# hssi_ss_csr: IP-XACT component
VLNV Vendor:Library:hssi_ss_csr:1.0

## Bus interfaces (logical=physical port)
hssi_ss_csr_slave: slave Magillem:MRV:MRVBusDef:1.0, memory map hssi_ss_csr
  parameters _mre_definition_=hssi_ss_csr

## Address spaces and blocks
hssi_ss_csr.hssi_ss_csr_block: base 0x0, range 0x118, width 32, register

## Registers
Registers are 32-bit, read-only, reset 0x0 unless marked. A register's access mark holds for its fields unless they carry their own. Offsets are from the block's base; lines under a group give offsets from that group; [hi:lo] are bit positions; {n}, {i} and the like mark numbered series; 'fields as' and 'values as' point back to an identical list; <NAME> marks a mode.

## hssi_ss_csr.hssi_ss_csr_block
Base 0x00000000
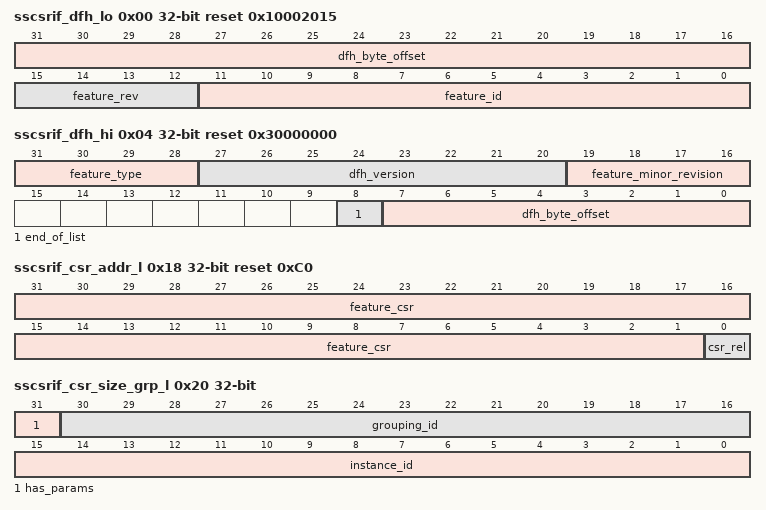
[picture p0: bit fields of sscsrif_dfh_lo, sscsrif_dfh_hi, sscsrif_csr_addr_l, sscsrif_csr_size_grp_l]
0x00 sscsrif_dfh_lo reset 0x10002015 — <b>Device Feature Header Lo </b>
  [31:16] dfh_byte_offset — <b>Next DFH Byte Offset Bit [15:0]</b> <b>Next DFH Address = 0x1000 (Current DFH Address + Next DFH Byte Offset Used to figure out Next DFH Address and as an indication for the maximum size of MMIO region occupied by this feature.</b> <b>For last feature, this offset points to the beginning of the unallocated MMIO region, if any (or beyond the end of the MMIOspace). </b>
  [15:12] feature_rev — <b>Feature Revision </b>
  [11:0] feature_id — <b>Feature ID </b>
0x04 sscsrif_dfh_hi reset 0x30000000 — <b>Device Feature Header Hi </b>
  [31:28] feature_type — <b>Feature Type </b> <p>4'b0011 - v0 feature/interface </p>
  [27:20] dfh_version — <b> DFH Version. It is 0 is CSR doesn't exist and 1 if CSR exist(for OSC).As per HAS, current version is v0.5 , till it is approved dfh version has to be 0x0 </b>
  [19:16] feature_minor_revision — <b> Feature Minor Revision </b>
  [8] end_of_list — <b>End of List </b> <p>1'b0 = This is last feature header (see Next DFH Byte Offset) </p>
  [7:0] dfh_byte_offset — <b>Next DFH Byte Offset Bit [39:32]</b> <b>Next DFH Address = 0x00 (Current DFH Address + Next DFH Byte Offset Used to figure out Next DFH Address and as an indication for the maximum size of MMIO region occupied by this feature.</b> <b>For last feature, this offset points to the beginning of the unallocated MMIO region, if any (or beyond the end of the MMIO space). </b>
0x08 sscsrif_feature_guid_l_low reset 0x18418B9D — <b> Feature GUID_L </b>
  [31:0] low_guid — <b> lower 32 bit of Low 64-bit of GUID </b>
0x0C sscsrif_feature_guid_l_high reset 0x99A078AD — <b> Feature GUID_L </b>
  [31:0] low_guid — <b> upper 32bit of Low 64-bit of GUID </b>
0x10 sscsrif_feature_guid_h_low reset 0xD9DB4A9B — <b> Feature GUID_H </b>
  [31:0] high_guid — <b> lower 32 bit of High 64-bit of GUID </b>
0x14 sscsrif_feature_guid_h_high reset 0x4118A7CB — <b> Feature GUID_H </b>
  [31:0] high_guid — <b> higher 32 bit of High 64-bit of GUID </b>
0x18 sscsrif_csr_addr_l reset 0xC0 — <b> Feature CSR ADDR </b>
  [31:1] feature_csr — <b> Points to where the IP/SS proprietary feature CSRs start. </b> <b> Need to provision space for future std DFH registers to grow </b> <b> For all IP/SS, this field shall point to 0x60 </b>
  [0] csr_rel — <b> Point to CSR located in a different address space which may be outside of PCI BAR, mainly for ARM </b> <b> 1'b0 = relative (offset from feature DFH start),1'b1 = absolute </b> <b> For all IP/SS, this field shall be 1b0. </b>
0x1C sscsrif_csr_addr_h — <b> Feature CSR ADDR </b>
  [31:0] feature_csr — <b> Points to where the IP/SS proprietary feature CSRs start. </b> <b> Need to provision space for future std DFH registers to grow </b> <b> For all IP/SS, this field shall point to 0x60 </b>
0x20 sscsrif_csr_size_grp_l — <b> Feature CSR Size Group </b>
  [31] has_params — <b> Indicates whether the optional Param Header and Param Y CSR are present or not. </b> <b> For all IP/SS, this field shall be 1b0 (no Param Header and no Param Y CSR) </b>
  [30:16] grouping_id — <b> Used to group features / interfaces . To differentiate & group different blocks within the pipeline </b> <b> For all IP/SS, this field is driver to zeros. </b>
  [15:0] instance_id — <b> Enumeration of instantiated IP </b> <b> A counter to differentiate each instances of the IP, advertise the instance ID assigned by Quartus </b> <b> To allow software to build the graph. Value derived from DFHv1_INSTID parameter </b>
0x24 sscsrif_csr_size_grp_h reset 0x44 — <b> Feature CSR Size Group </b>
  [31:0] csr_size — <b> Size of CSR block in bytes </b> <b> Specifies the size of the IP/SS proprietary feature CSR in Bytes </b>
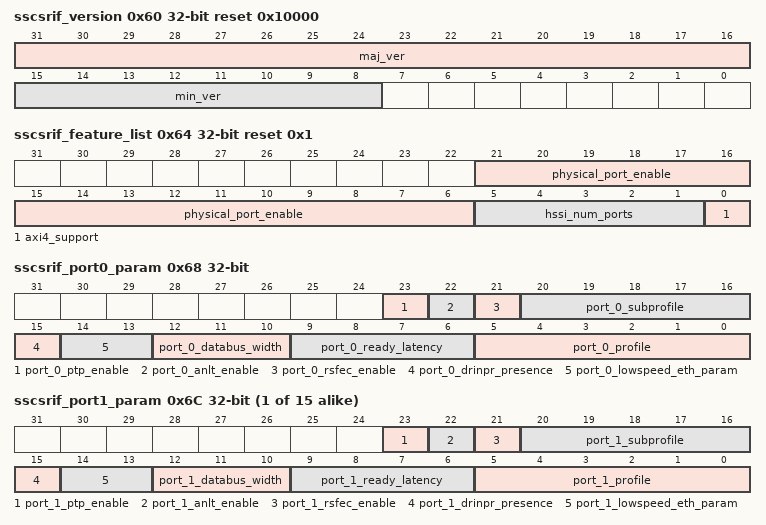
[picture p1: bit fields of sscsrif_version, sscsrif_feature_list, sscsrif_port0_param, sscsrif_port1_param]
0x60 sscsrif_version reset 0x10000 — <b>Version </b>
  [31:16] maj_ver — <b>Major Version Number (MNR): Indicates the Major version.</b>
  [15:8] min_ver — <b>Minor Version Number (MNR): Indicates the minor version.</b>
0x64 sscsrif_feature_list reset 0x1 — <b>Feature List </b>
  [21:6] physical_port_enable — <b>Physical Port Enable </b> <p>[ 6] - Port 0 Enable </p> <p>[ 7] - Port 1 Enable </p> <p> . </p> <p> . </p> <p>[21] - Port 15 Enable </p>
  [5:1] hssi_num_ports — <b>Number of HSSI Ports Instantiated (NUM_PORTS parameter) </b>
  [0] axi4_support — <b>AXI-4 Support </b>
0x68 sscsrif_port0_param — <b>Interface Attribute Port 0 Parameters, (Depends on NUM_PORTS parameter, read returns reserved value 0 if port does not exist) </b>
  [23] port_0_ptp_enable — <b>PTP Enabled </b>
  [22] port_0_anlt_enable — <b>ANLT Enabled </b>
  [21] port_0_rsfec_enable — <b>RSFEC Enabled </b>
  [20:16] port_0_subprofile — <b>Port 0 Sub-Profiles. </b> <p>5'b10000 and above - Reserved</p> <p>5'b01111 - 24G PCS </p> <p>5'b01110 - 12G PCS </p> <p>5'b01101 - 10G PCS </p> <p>5'b01100 - 9.8G PMA </p> <p>5'b01011 - 8.1G PMA </p> <p>5'b01010 - 6.1G PMA </p> <p>5'b01001 - 4.9G PMA </p> <p>5'b01000 - 3.0G PMA </p> <p>5'b00111 - 2.4G PMA </p> <p>5'b00110 - 1.2G PMA </p> <p>5'b00101 - 0.6G PMA </p> <p>5'b00100 - MAC + PCS </p> <p>5'b00011 - PCS </p> <p>5'b00010 - FlexE </p> <p>5'b00001 - OTN </p> <p>5'b00000 - None </p>
  [15] port_0_drinpr_presence — <b>Indicate presence of Dynamic Reconfiguration in Partial Reconfiguration use case.</b> <p>1: Dynamic Reconfiguration in Partial Reconfiguration use case presence </p> <p>0: Dynamic Reconfiguration in Partial Reconfiguration use case not presence </p>
  [14:13] port_0_lowspeed_eth_param — <b>Low Speed Ethernet MAC Interface (PORT0_LOW_SPEED_ETH parameter).</b> <p>2'b10: XGMII </p> <p>2'b01: GMII </p> <p>2'b00: MII </p>
  [12:10] port_0_databus_width — <b>Port 0 Data Bus Width (PORT0_DATA_WIDTH parameter).</b> <p>3'b101: 1024 </p> <p>3'b100: 512 </p> <p>3'b011: 256 </p> <p>3'b010: 128 </p> <p>3'b001: 64 </p> <p>3'b000: 32 </p>
  [9:6] port_0_ready_latency — <b>Port 0 Ready Latency (PORT0_READY_LATENCY parameter).</b>
  [5:0] port_0_profile — <b>Port 0 Profiles (PORT0_PROFILE).</b> <p>6'b100000: 400GAUI-8, </p> <p>6'b011111: 400GAUI-4, </p> <p>6'b011110: 200GAUI-8, </p> <p>6'b011101: 200GAUI-4, </p> <p>6'b011100: 200GAUI-2, </p> <p>6'b011011: 100GCAUI-4, </p> <p>6'b011010: 100GAUI-2, </p> <p>6'b011001: 100GAUI-1, </p> <p>6'b011000: 50GAUI-1, </p> <p>6'b010111: 50GAUI-2, </p> <p>6'b010110: 40GCAUI-4, </p> <p>6'b010101: 25GbE, </p> <p>6'b010100: 10GbE, </p> <p>6'b010011: Ethernet PMA-Direct,</p> <p>6'b010010: Ethernet FEC-Direct,</p> <p>6'b010001: Ethernet PCS-Direct,</p> <p>6'b010000: MII, </p> <p>6'b001111: General PMA-Direct, </p> <p>6'b001110: General FEC-Direct, </p> <p>6'b001101: General PCS-Direct, </p> <p>6'b001100: OTN, </p> <p>6'b001011: Flex-E, </p> <p>6'b001010: TSE MAC, </p> <p>6'b001001: TSE PCS, </p> <p>6'b001000: LL10G, </p> <p>6'b000111: MRPHY, </p> <p>6'b000110: 10_25G, </p> <p>6'b000101: 25_50G, </p> <p>6'b000100: Ultra40G, </p> <p>6'b000011: LL40G, </p> <p>6'b000010: LL50G, </p> <p>6'b000001: Ultra100G, </p> <p>6'b000000: LL100G </p>
{0x68+4i} sscsrif_port{i}_param (i=1..15) — <b>Interface Attribute Port {i} Parameters, (Depends on NUM_PORTS parameter, read returns reserved value 0 if port does not exist) </b>
  [23] port_{i}_ptp_enable — <b>PTP Enabled </b>
  [22] port_{i}_anlt_enable — <b>ANLT Enabled </b>
  [21] port_{i}_rsfec_enable — <b>RSFEC Enabled </b>
  [20:16] port_{i}_subprofile — <b>Port {i} Sub-Profiles.</b> <p>6'b100000: 400GAUI-8, </p> <p>6'b011111: 400GAUI-4, </p> <p>6'b011110: 200GAUI-8, </p> <p>6'b011101: 200GAUI-4, </p> <p>6'b011100: 200GAUI-2, </p> <p>6'b011011: 100GCAUI-4, </p> <p>6'b011010: 100GAUI-2, </p> <p>6'b011001: 100GAUI-1, </p> <p>6'b011000: 50GAUI-1, </p> <p>6'b010111: 50GAUI-2, </p> <p>6'b010110: 40GCAUI-4, </p> <p>6'b010101: 25GbE, </p> <p>6'b010100: 10GbE, </p> <p>6'b010011: Ethernet PMA-Direct,</p> <p>6'b010010: Ethernet FEC-Direct,</p> <p>6'b010001: Ethernet PCS-Direct,</p> <p>6'b010000: MII, </p> <p>6'b001111: General PMA-Direct, </p> <p>6'b001110: General FEC-Direct, </p> <p>6'b001101: General PCS-Direct, </p> <p>6'b001100: OTN, </p> <p>6'b001011: Flex-E, </p> <p>6'b001010: TSE MAC, </p> <p>6'b001001: TSE PCS, </p> <p>6'b001000: LL10G, </p> <p>6'b000111: MRPHY, </p> <p>6'b000110: 10_25G, </p> <p>6'b000101: 25_50G, </p> <p>6'b000100: Ultra40G, </p> <p>6'b000011: LL40G, </p> <p>6'b000010: LL50G, </p> <p>6'b000001: Ultra100G, </p> <p>6'b000000: LL100G </p>
  [15] port_{i}_drinpr_presence — <b>Indicate presence of Dynamic Reconfiguration in Partial Reconfiguration use case.</b> <p>1: Dynamic Reconfiguration in Partial Reconfiguration use case presence </p> <p>0: Dynamic Reconfiguration in Partial Reconfiguration use case not presence </p>
  [14:13] port_{i}_lowspeed_eth_param — <b>Low Speed Ethernet MAC Interface (PORT{i}_LOW_SPEED_ETH parameter).</b> <p>2'b10: XGMII </p> <p>2'b01: GMII </p> <p>2'b00: MII </p>
  [12:10] port_{i}_databus_width — <b>Port {i} Data Bus Width (PORT{i}_DATA_WIDTH parameter).</b> <p>3'b101: 1024 </p> <p>3'b100: 512 </p> <p>3'b011: 256 </p> <p>3'b010: 128 </p> <p>3'b001: 64 </p> <p>3'b000: 32 </p>
  [9:6] port_{i}_ready_latency — <b>Port {i} Ready Latency (PORT{i}_READY_LATENCY parameter).</b>
  [5:0] port_{i}_profile — <b>Port {i} Profiles (PORT{i}_PROFILE).</b> <p>6'b100000: 400GAUI-8, </p> <p>6'b011111: 400GAUI-4, </p> <p>6'b011110: 200GAUI-8, </p> <p>6'b011101: 200GAUI-4, </p> <p>6'b011100: 200GAUI-2, </p> <p>6'b011011: 100GCAUI-4, </p> <p>6'b011010: 100GAUI-2, </p> <p>6'b011001: 100GAUI-1, </p> <p>6'b011000: 50GAUI-1, </p> <p>6'b010111: 50GAUI-2, </p> <p>6'b010110: 40GCAUI-4, </p> <p>6'b010101: 25GbE, </p> <p>6'b010100: 10GbE, </p> <p>6'b010011: Ethernet PMA-Direct,</p> <p>6'b010010: Ethernet FEC-Direct,</p> <p>6'b010001: Ethernet PCS-Direct,</p> <p>6'b010000: MII, </p> <p>6'b001111: General PMA-Direct, </p> <p>6'b001110: General FEC-Direct, </p> <p>6'b001101: General PCS-Direct, </p> <p>6'b001100: OTN, </p> <p>6'b001011: Flex-E, </p> <p>6'b001010: TSE MAC, </p> <p>6'b001001: TSE PCS, </p> <p>6'b001000: LL10G, </p> <p>6'b000111: MRPHY, </p> <p>6'b000110: 10_25G, </p> <p>6'b000101: 25_50G, </p> <p>6'b000100: Ultra40G, </p> <p>6'b000011: LL40G, </p> <p>6'b000010: LL50G, </p> <p>6'b000001: Ultra100G, </p> <p>6'b000000: LL100G </p>
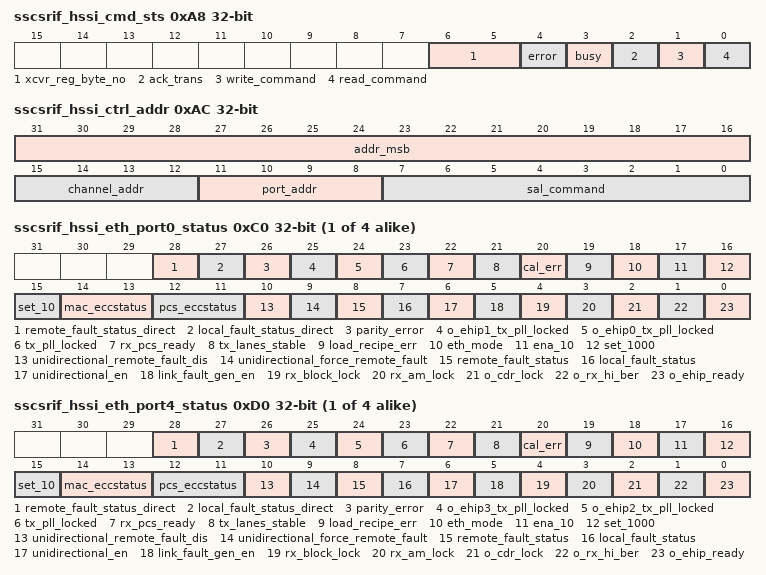
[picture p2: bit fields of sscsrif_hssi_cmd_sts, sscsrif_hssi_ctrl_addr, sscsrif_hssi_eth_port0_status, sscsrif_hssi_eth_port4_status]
0xA8 sscsrif_hssi_cmd_sts rw — <b>HSSI Command/Status </b>
  [6:5] xcvr_reg_byte_no — <b>XCVR Reg Byte Num </b>
  [4] error ro
  [3] busy ro
  [2] ack_trans — <b>ACK_TRANS: Bit gets asserted by hw when transaction is complete. Gets cleared by hw, when hw receives the next command. </b> <p> 0- indicates, a command is getting processed.</p> <p> 1- Indicates, the earlier command processing is complete and it's ready to accept next command.</p>
  [1] write_command — <b>Write Command </b>
  [0] read_command — <b>Read Command </b>
0xAC sscsrif_hssi_ctrl_addr rw — <b>HSSI Control 1 </b>
  [31:16] addr_msb — <b>Address bit [23:8] </b>
  [15:12] channel_addr — <b>Channel/Address:</b> <p>When SAL command = get_hssi_profile, set_hssi_profile, enable loopback, disable loopback, [15:12] = Channel</p> <p>When SAL command = get_csr, set_csr, [15:12] = Address[7:4]</p> <p>Others, [15:12] = 4'b0 </p>
  [11:8] port_addr — <b>Port/Address: </b> <p>When SAL command = get_hssi_profile, set_hssi_profile, enable loopback, disable loopback, [11:8] = Port</p> <p>When SAL command = get_csr, set_csr, [11:8] = Address[3:0]</p> <p>Others[11:8] = 4'b0 </p>
  [7:0] sal_command — <b>RSAL Command:</b> <p>0x0 NOP </p> <p>0x1 get_hssi_profile </p> <p>0x2 set_hssi_profile </p> <p>0x3 read_MAC_statistic </p> <p>0x4 get_mtu </p> <p>0x5 Set CSR </p> <p>0x6 Get CSR </p> <p>0x7 Enable loopback </p> <p>0x8 Disable loopback </p> <p>0x9 - 0xFE reserved </p> <p>0xFF firmware_versionserved </p>
0xB0 sscsrif_hssi_rd_data — <b>HSSI Read Data </b>
  [31:0] write_data — <b>Read data </b>
0xB4 sscsrif_hssi_wr_data rw — <b>HSSI Write Data </b>
  [31:0] write_data — <b>Write data </b>
0xB8 sscsrif_gmii_xgmii_tx_latency — <b>GMII/XGMII TX Latency </b>
  [23:0] tx_latency — <b>gmii_tx_latency/xgmii_tx_latency </b> <b>The latency of the PHY excluding the PMA block on the TX datapath:</b> <p>Bits [15:10], [21:10] and [23:10]: The number of clock cycles.</p> <p>Bits [9:0]: The fractional number of clock cycles.</p> <p>The width is:</p> <p>16 bits for 1G/2.5G/10G (MGBASE-T) with IEEE 1588 configurations.</p> <p>22 bits for 2.5G, 1G/2.5G, 10M/100M/1G/2.5G, 1G/2.5G/10G (MGBASE-T),10M/100M/1G/2.5G/10G(MGBASE-T)</p> <p>24 bits for 10M/100M/1G/2.5G/5G/10G (USXGMII) configurations.</p> <b>This signal is available when only the Enable IEEE 1588 Precision Time Protocol parameter is selected.</b> <b>Note:</b> <b>For USXGMII configuration, the latency value may be unstable for the first three transmitted packets times (at least 64 bytes). You should not use the latency value within this period. Only applicable for MRPHY profile. Reserved for other profiles.</b>
0xBC sscsrif_gmii_xgmii_rx_latency — <b>GMII/XGMII RX Latency </b>
  [23:0] rx_latency — <b>gmii_rx_latency/xgmii_rx_latency </b> <b>The latency of the PHY excluding the PMA block on the TX datapath:</b> <p>Bits [15:10], [21:10] and [23:10]: The number of clock cycles.</p> <p>Bits [9:0]: The fractional number of clock cycles.</p> <p>The width is:</p> <p>16 bits for 1G/2.5G/10G (MGBASE-T) with IEEE 1588 configurations.</p> <p>22 bits for 2.5G, 1G/2.5G, 10M/100M/1G/2.5G, 1G/2.5G/10G (MGBASE-T),10M/100M/1G/2.5G/10G(MGBASE-T)</p> <p>24 bits for 10M/100M/1G/2.5G/5G/10G (USXGMII) configurations.</p> <b>This signal is available when only the Enable IEEE 1588 Precision Time Protocol parameter is selected.</b> <b>Note:</b> <b>For USXGMII configuration, the latency value may be unstable for the first three transmitted packets times (at least 64 bytes). You should not use the latency value within this period. Only applicable for MRPHY profile. Reserved for other profiles.</b>
{0xC0+4i} sscsrif_hssi_eth_port{i}_status rw (i=0..3) — <b>HSSI Ethernet port{i} Status (Depends on NUM_PORTS parameter, read returns reserved value 0 if port does not exist) </b>
  [28] remote_fault_status_direct ro — <b>remote_fault_status:</b> <p>Asserted when the RX MAC of the corresponding Ethernet channel detects a remote fault: the remote link partner sent remote fault ordered sets indicating that it is unable to receive data. This signal is functional only if you set the Choose Link Fault generation option parameter to the value of Bidirectional in the parameter editor or if you overwrite the parameter editor parameter by setting the link_fault_mode RTL parameter to the value of lf_bidir.</p>
  [27] local_fault_status_direct ro — <b>local_fault_status:</b> <p>Asserted when the RX MAC of the corresponding Ethernet channel detects a local fault: the RX PCS detected a problem that prevents it from receiving data. This signal is functional only if you set the Choose Link Fault generation option parameter to the value of Bidirectional or Unidirectional in the parameter editor or if you overwrite the parameter editor parameter by setting the link_fault_mode RTL parameter to the value of lf_bidir or lf_unidir. </p>
  [26] parity_error write-1-clears — <b>Parity Error on received packet </b>
  [25] o_ehip1_tx_pll_locked ro — <b>o_ehip1_tx_pll_locked: </b> <p> PTP channels Tx_pll_locked (o_ehip{0..NUM_PORT/2}_tx_pll_locked, applicable only in E-tile. </p>
  [24] o_ehip0_tx_pll_locked ro — <b>o_ehip0_tx_pll_locked: </b> <p> PTP channels Tx_pll_locked (o_ehip{0..NUM_PORT/2}_tx_pll_locked, applicable only in E-tile. </p>
  [23] tx_pll_locked ro — <b>Tx_pll_locked: </b> <p> Tx Ethernet port pll lock </p>
  [22] rx_pcs_ready ro — <b>Rx_pcs_ready:</b> <p> Asserted when the RX lanes of the corresponding Ethernet port are fully aligned and ready to receive data. </p>
  [21] tx_lanes_stable ro — <b>Tx_lanes_stable:</b> <p> Asserted when physical TX lanes are stable and ready to transmit data for the corresponding Ethernet port. </p>
  [20] cal_err ro — <b>cal_err:</b> <p>Calibration Error Status.This bit reports the error status of ical/pcal at power on. </p>
  [19] load_recipe_err ro — <b>load_recipe_err:</b> <p>Load Recipe Error Status.This bit reports the error status of load PMA recipe at power on. </p>
  [18] eth_mode ro — <b>eth_mode:</b> <p>Ethernet mode. This signal is set to 1 when the MAC function is configured to operate at 1000 Mbps; set to 0 when it is configured to operate at 10/100 Mbps. Only applicable for TSE_MAC profile. Reserved for other profiles. </p>
  [17] ena_10 ro — <b>ena_10:</b> <p>10 Mbps enable. This signal is set to 1 to indicate that the PHY interface should operate at 10 Mbps. Valid only when the eth_mode signal is set to 0. Only applicable for TSE_MAC profile. Reserved for other profiles. </p>
  [16] set_1000 ro — <b>set_1000:</b> <p>Gigabit mode selection. Can be driven to 1 by an external device, for example a PHY device, to set the MAC function to operate in gigabit. When set to 0, the MAC is set to operate in 10/100 Mbps. This signal is ignored when the ETH_SPEED bit in the command_config register is set to 1. Only applicable for TSE_MAC profile. Reserved for other profiles. </p>
  [15] set_10 ro — <b>set_10:</b> <p>10 Mbps selection. Can be driven to 1 by an external device, for example a PHY device, to indicate that the MAC function is connected to a 10-Mbps PHY device. When set to 0, the MAC function is set to operate in 100-Mbps or gigabit mode. This signal is ignored when the ETH_SPEED or ENA_10 bit in the command_config register is set to 1. The ENA_10 bit has a higher priority than this signal. Only applicable for TSE_MAC profile. Reserved for other profiles. </p>
  [14:13] mac_eccstatus ro — <b>mac_eccstatus[1:0]:</b> <p>Indicates the ECC status. This signal is synchronized to the reg_clk clock domain. 11: An uncorrectable error occurred and the error data appears at the output. 10: A correctable error occurred and the error has been corrected at the output. However, the memory array has not been updated. 01: Not valid. 00: No error. Only applicable for TSE_MAC profile. Reserved for other profiles. </p>
  [12:11] pcs_eccstatus ro — <b>pcs_eccstatus[1:0]:</b> <p>Indicates the ECC status. This signal is synchronized to the reg_clk clock domain. 11: An uncorrectable error occurred and the error data appears at the output. 10: A correctable error occurred and the error has been corrected at the output. However, the memory array has not been updated. 01: Not valid. 00: No error Only applicable for TSE_PCS profile. Reserved for other profiles. </p>
  [10] unidirectional_remote_fault_dis ro — <b>unidirectional_remote_fault_dis:</b> <p>When asserted, this signal indicates the state of the tx_unidir_control register bit 1. </p>
  [9] unidirectional_force_remote_fault ro — <b>unidirectional_force_remote_fault:</b> <p>When asserted, this signal indicates the state of the tx_unidir_control register bit 2. </p>
  [8] remote_fault_status write-1-clears — <b>remote_fault_status:</b> <p>Asserted when the RX MAC of the corresponding Ethernet channel detects a remote fault: the remote link partner sent remote fault ordered sets indicating that it is unable to receive data. This signal is functional only if you set the Choose Link Fault generation option parameter to the value of Bidirectional in the parameter editor or if you overwrite the parameter editor parameter by setting the link_fault_mode RTL parameter to the value of lf_bidir.</p>
  [7] local_fault_status write-1-clears — <b>local_fault_status:</b> <p>Asserted when the RX MAC of the corresponding Ethernet channel detects a local fault: the RX PCS detected a problem that prevents it from receiving data. This signal is functional only if you set the Choose Link Fault generation option parameter to the value of Bidirectional or Unidirectional in the parameter editor or if you overwrite the parameter editor parameter by setting the link_fault_mode RTL parameter to the value of lf_bidir or lf_unidir. </p>
  [6] unidirectional_en ro — <b>unidirectional_en:</b> <p>Asserted if the IP core includes Clause 66 for unidirectional support. This signal is available if you turn on Enable link fault generation in the parameter editor. </p>
  [5] link_fault_gen_en ro — <b>link_fault_gen_en:</b> <p>Asserted if the IP core includes Clause 66 for unidirectional support. This signal is available if you turn on Enable link fault generation in the parameter editor. </p>
  [4] rx_block_lock ro — <b>rx_block_lock:</b> <p>Asserted when the corresponding Ethernet channel completes 66-bit block boundary alignment on all PCS lanes. Each channel has its own block lock signal. </p>
  [3] rx_am_lock ro — <b>rx_am_lock:</b> <p>Asserted when the RX PCS completes detection of alignment markers and deskew of the virtual PCS lanes in the corresponding Ethernet 100G channel. </p>
  [2] o_cdr_lock ro — <b>o_cdr_lock:</b> <p>Indicates that the recovered clocks are locked to data. The o_clk_rec_div64[n] and o_clk_rec_div66[n] clocks are reliable only after o_cdr_lock[n] is asserted. </p>
  [1] o_rx_hi_ber ro — <b>o_rx_hi_ber:</b> <p>Asserted to indicate the RX PCS of the corresponding Ethernet channel is in a HI BER state according to Figure 82-15 in the IEEE 802.3- 2015 Standard. The IP core uses this signal in autonegotiation and link training. </p>
  [0] o_ehip_ready ro — <b>o_ehip_ready:</b> <p>The Ethernet channel deasserts this signal in response to an i_csr_rst_n or i_tx_rst_n reset, or either of the corresponding soft resets. After the reset process completes, the channel reasserts this signal to indicate that the Hard IP for Ethernet block has completed initialization and is ready to interoperate with the main Intel Stratix 10 die. While the o_ehip_ready signal is low, the channel's datapath is not ready for data on the client interface nor ready for register accesses on the Ethernet reconfiguration interface.</p>
{0xC0+4i} sscsrif_hssi_eth_port{i}_status rw (i=4..7) — <b>HSSI Ethernet port{i} Status (Depends on NUM_PORTS parameter, read returns reserved value 0 if port does not exist) </b>
  [28] remote_fault_status_direct ro — <b>remote_fault_status:</b> <p>Asserted when the RX MAC of the corresponding Ethernet channel detects a remote fault: the remote link partner sent remote fault ordered sets indicating that it is unable to receive data. This signal is functional only if you set the Choose Link Fault generation option parameter to the value of Bidirectional in the parameter editor or if you overwrite the parameter editor parameter by setting the link_fault_mode RTL parameter to the value of lf_bidir.</p>
  [27] local_fault_status_direct ro — <b>local_fault_status:</b> <p>Asserted when the RX MAC of the corresponding Ethernet channel detects a local fault: the RX PCS detected a problem that prevents it from receiving data. This signal is functional only if you set the Choose Link Fault generation option parameter to the value of Bidirectional or Unidirectional in the parameter editor or if you overwrite the parameter editor parameter by setting the link_fault_mode RTL parameter to the value of lf_bidir or lf_unidir. </p>
  [26] parity_error write-1-clears — <b>Parity Error on received packet </b>
  [25] o_ehip3_tx_pll_locked ro — <b>o_ehip3_tx_pll_locked: </b> <p> PTP channels Tx_pll_locked (o_ehip{0..NUM_PORT/2}_tx_pll_locked, applicable only in E-tile. </p>
  [24] o_ehip2_tx_pll_locked ro — <b>o_ehip2_tx_pll_locked: </b> <p> PTP channels Tx_pll_locked (o_ehip{0..NUM_PORT/2}_tx_pll_locked, applicable only in E-tile. </p>
  [23] tx_pll_locked ro — <b>Tx_pll_locked: </b> <p> Tx Ethernet port pll lock </p>
  [22] rx_pcs_ready ro — <b>Rx_pcs_ready:</b> <p> Asserted when the RX lanes of the corresponding Ethernet port are fully aligned and ready to receive data. </p>
  [21] tx_lanes_stable ro — <b>Tx_lanes_stable:</b> <p> Asserted when physical TX lanes are stable and ready to transmit data for the corresponding Ethernet port. </p>
  [20] cal_err ro — <b>cal_err:</b> <p>Calibration Error Status.This bit reports the error status of ical/pcal at power on. </p>
  [19] load_recipe_err ro — <b>load_recipe_err:</b> <p>Load Recipe Error Status.This bit reports the error status of load PMA recipe at power on. </p>
  [18] eth_mode ro — <b>eth_mode:</b> <p>Ethernet mode. This signal is set to 1 when the MAC function is configured to operate at 1000 Mbps; set to 0 when it is configured to operate at 10/100 Mbps. Only applicable for TSE_MAC profile. Reserved for other profiles. </p>
  [17] ena_10 ro — <b>ena_10:</b> <p>10 Mbps enable. This signal is set to 1 to indicate that the PHY interface should operate at 10 Mbps. Valid only when the eth_mode signal is set to 0. Only applicable for TSE_MAC profile. Reserved for other profiles. </p>
  [16] set_1000 ro — <b>set_1000:</b> <p>Gigabit mode selection. Can be driven to 1 by an external device, for example a PHY device, to set the MAC function to operate in gigabit. When set to 0, the MAC is set to operate in 10/100 Mbps. This signal is ignored when the ETH_SPEED bit in the command_config register is set to 1. Only applicable for TSE_MAC profile. Reserved for other profiles. </p>
  [15] set_10 ro — <b>set_10:</b> <p>10 Mbps selection. Can be driven to 1 by an external device, for example a PHY device, to indicate that the MAC function is connected to a 10-Mbps PHY device. When set to 0, the MAC function is set to operate in 100-Mbps or gigabit mode. This signal is ignored when the ETH_SPEED or ENA_10 bit in the command_config register is set to 1. The ENA_10 bit has a higher priority than this signal. Only applicable for TSE_MAC profile. Reserved for other profiles. </p>
  [14:13] mac_eccstatus ro — <b>mac_eccstatus[1:0]:</b> <p>Indicates the ECC status. This signal is synchronized to the reg_clk clock domain. 11: An uncorrectable error occurred and the error data appears at the output. 10: A correctable error occurred and the error has been corrected at the output. However, the memory array has not been updated. 01: Not valid. 00: No error. Only applicable for TSE_MAC profile. Reserved for other profiles. </p>
  [12:11] pcs_eccstatus ro — <b>pcs_eccstatus[1:0]:</b> <p>Indicates the ECC status. This signal is synchronized to the reg_clk clock domain. 11: An uncorrectable error occurred and the error data appears at the output. 10: A correctable error occurred and the error has been corrected at the output. However, the memory array has not been updated. 01: Not valid. 00: No error Only applicable for TSE_PCS profile. Reserved for other profiles. </p>
  [10] unidirectional_remote_fault_dis ro — <b>unidirectional_remote_fault_dis:</b> <p>When asserted, this signal indicates the state of the tx_unidir_control register bit 1. </p>
  [9] unidirectional_force_remote_fault ro — <b>unidirectional_force_remote_fault:</b> <p>When asserted, this signal indicates the state of the tx_unidir_control register bit 2. </p>
  [8] remote_fault_status write-1-clears — <b>remote_fault_status:</b> <p>Asserted when the RX MAC of the corresponding Ethernet channel detects a remote fault: the remote link partner sent remote fault ordered sets indicating that it is unable to receive data. This signal is functional only if you set the Choose Link Fault generation option parameter to the value of Bidirectional in the parameter editor or if you overwrite the parameter editor parameter by setting the link_fault_mode RTL parameter to the value of lf_bidir.</p>
  [7] local_fault_status write-1-clears — <b>local_fault_status:</b> <p>Asserted when the RX MAC of the corresponding Ethernet channel detects a local fault: the RX PCS detected a problem that prevents it from receiving data. This signal is functional only if you set the Choose Link Fault generation option parameter to the value of Bidirectional or Unidirectional in the parameter editor or if you overwrite the parameter editor parameter by setting the link_fault_mode RTL parameter to the value of lf_bidir or lf_unidir. </p>
  [6] unidirectional_en ro — <b>unidirectional_en:</b> <p>Asserted if the IP core includes Clause 66 for unidirectional support. This signal is available if you turn on Enable link fault generation in the parameter editor. </p>
  [5] link_fault_gen_en ro — <b>link_fault_gen_en:</b> <p>Asserted if the IP core includes Clause 66 for unidirectional support. This signal is available if you turn on Enable link fault generation in the parameter editor. </p>
  [4] rx_block_lock ro — <b>rx_block_lock:</b> <p>Asserted when the corresponding Ethernet channel completes 66-bit block boundary alignment on all PCS lanes. Each channel has its own block lock signal. </p>
  [3] rx_am_lock ro — <b>rx_am_lock:</b> <p>Asserted when the RX PCS completes detection of alignment markers and deskew of the virtual PCS lanes in the corresponding Ethernet 100G channel. </p>
  [2] o_cdr_lock ro — <b>o_cdr_lock:</b> <p>Indicates that the recovered clocks are locked to data. The o_clk_rec_div64[n] and o_clk_rec_div66[n] clocks are reliable only after o_cdr_lock[n] is asserted. </p>
  [1] o_rx_hi_ber ro — <b>o_rx_hi_ber:</b> <p>Asserted to indicate the RX PCS of the corresponding Ethernet channel is in a HI BER state according to Figure 82-15 in the IEEE 802.3- 2015 Standard. The IP core uses this signal in autonegotiation and link training. </p>
  [0] o_ehip_ready ro — <b>o_ehip_ready:</b> <p>The Ethernet channel deasserts this signal in response to an i_csr_rst_n or i_tx_rst_n reset, or either of the corresponding soft resets. After the reset process completes, the channel reasserts this signal to indicate that the Hard IP for Ethernet block has completed initialization and is ready to interoperate with the main Intel Stratix 10 die. While the o_ehip_ready signal is low, the channel's datapath is not ready for data on the client interface nor ready for register accesses on the Ethernet reconfiguration interface.</p>
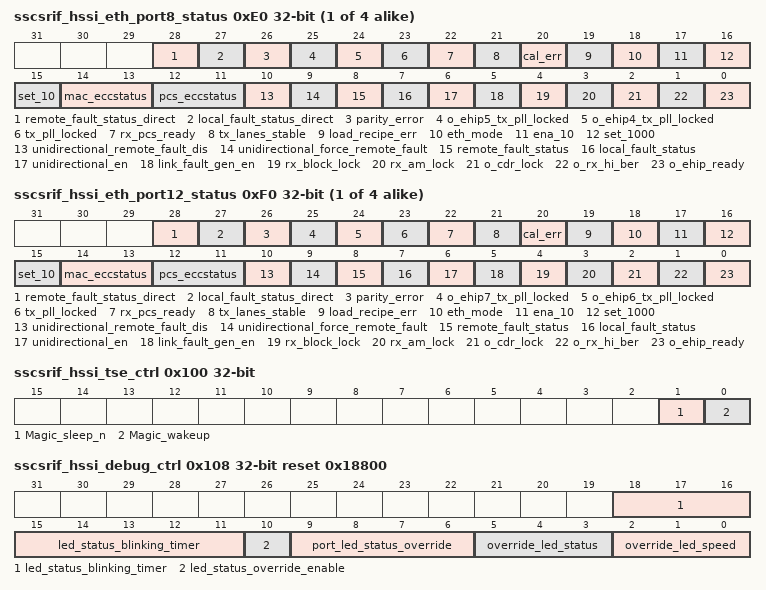
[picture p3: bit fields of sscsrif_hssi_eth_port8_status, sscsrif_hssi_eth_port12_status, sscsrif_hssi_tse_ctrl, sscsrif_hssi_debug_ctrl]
{0xC0+4i} sscsrif_hssi_eth_port{i}_status rw (i=8..11) — <b>HSSI Ethernet port{i} Status (Depends on NUM_PORTS parameter, read returns reserved value 0 if port does not exist) </b>
  [28] remote_fault_status_direct ro — <b>remote_fault_status:</b> <p>Asserted when the RX MAC of the corresponding Ethernet channel detects a remote fault: the remote link partner sent remote fault ordered sets indicating that it is unable to receive data. This signal is functional only if you set the Choose Link Fault generation option parameter to the value of Bidirectional in the parameter editor or if you overwrite the parameter editor parameter by setting the link_fault_mode RTL parameter to the value of lf_bidir.</p>
  [27] local_fault_status_direct ro — <b>local_fault_status:</b> <p>Asserted when the RX MAC of the corresponding Ethernet channel detects a local fault: the RX PCS detected a problem that prevents it from receiving data. This signal is functional only if you set the Choose Link Fault generation option parameter to the value of Bidirectional or Unidirectional in the parameter editor or if you overwrite the parameter editor parameter by setting the link_fault_mode RTL parameter to the value of lf_bidir or lf_unidir. </p>
  [26] parity_error write-1-clears — <b>Parity Error on received packet </b>
  [25] o_ehip5_tx_pll_locked ro — <b>o_ehip5_tx_pll_locked: </b> <p> PTP channels Tx_pll_locked (o_ehip{0..NUM_PORT/2}_tx_pll_locked, applicable only in E-tile. </p>
  [24] o_ehip4_tx_pll_locked ro — <b>o_ehip4_tx_pll_locked: </b> <p> PTP channels Tx_pll_locked (o_ehip{0..NUM_PORT/2}_tx_pll_locked, applicable only in E-tile. </p>
  [23] tx_pll_locked ro — <b>Tx_pll_locked: </b> <p> Tx Ethernet port pll lock </p>
  [22] rx_pcs_ready ro — <b>Rx_pcs_ready:</b> <p> Asserted when the RX lanes of the corresponding Ethernet port are fully aligned and ready to receive data. </p>
  [21] tx_lanes_stable ro — <b>Tx_lanes_stable:</b> <p> Asserted when physical TX lanes are stable and ready to transmit data for the corresponding Ethernet port. </p>
  [20] cal_err ro — <b>cal_err:</b> <p>Calibration Error Status.This bit reports the error status of ical/pcal at power on. </p>
  [19] load_recipe_err ro — <b>load_recipe_err:</b> <p>Load Recipe Error Status.This bit reports the error status of load PMA recipe at power on. </p>
  [18] eth_mode ro — <b>eth_mode:</b> <p>Ethernet mode. This signal is set to 1 when the MAC function is configured to operate at 1000 Mbps; set to 0 when it is configured to operate at 10/100 Mbps. Only applicable for TSE_MAC profile. Reserved for other profiles. </p>
  [17] ena_10 ro — <b>ena_10:</b> <p>10 Mbps enable. This signal is set to 1 to indicate that the PHY interface should operate at 10 Mbps. Valid only when the eth_mode signal is set to 0. Only applicable for TSE_MAC profile. Reserved for other profiles. </p>
  [16] set_1000 ro — <b>set_1000:</b> <p>Gigabit mode selection. Can be driven to 1 by an external device, for example a PHY device, to set the MAC function to operate in gigabit. When set to 0, the MAC is set to operate in 10/100 Mbps. This signal is ignored when the ETH_SPEED bit in the command_config register is set to 1. Only applicable for TSE_MAC profile. Reserved for other profiles. </p>
  [15] set_10 ro — <b>set_10:</b> <p>10 Mbps selection. Can be driven to 1 by an external device, for example a PHY device, to indicate that the MAC function is connected to a 10-Mbps PHY device. When set to 0, the MAC function is set to operate in 100-Mbps or gigabit mode. This signal is ignored when the ETH_SPEED or ENA_10 bit in the command_config register is set to 1. The ENA_10 bit has a higher priority than this signal. Only applicable for TSE_MAC profile. Reserved for other profiles. </p>
  [14:13] mac_eccstatus ro — <b>mac_eccstatus[1:0]:</b> <p>Indicates the ECC status. This signal is synchronized to the reg_clk clock domain. 11: An uncorrectable error occurred and the error data appears at the output. 10: A correctable error occurred and the error has been corrected at the output. However, the memory array has not been updated. 01: Not valid. 00: No error. Only applicable for TSE_MAC profile. Reserved for other profiles. </p>
  [12:11] pcs_eccstatus ro — <b>pcs_eccstatus[1:0]:</b> <p>Indicates the ECC status. This signal is synchronized to the reg_clk clock domain. 11: An uncorrectable error occurred and the error data appears at the output. 10: A correctable error occurred and the error has been corrected at the output. However, the memory array has not been updated. 01: Not valid. 00: No error Only applicable for TSE_PCS profile. Reserved for other profiles. </p>
  [10] unidirectional_remote_fault_dis ro — <b>unidirectional_remote_fault_dis:</b> <p>When asserted, this signal indicates the state of the tx_unidir_control register bit 1. </p>
  [9] unidirectional_force_remote_fault ro — <b>unidirectional_force_remote_fault:</b> <p>When asserted, this signal indicates the state of the tx_unidir_control register bit 2. </p>
  [8] remote_fault_status write-1-clears — <b>remote_fault_status:</b> <p>Asserted when the RX MAC of the corresponding Ethernet channel detects a remote fault: the remote link partner sent remote fault ordered sets indicating that it is unable to receive data. This signal is functional only if you set the Choose Link Fault generation option parameter to the value of Bidirectional in the parameter editor or if you overwrite the parameter editor parameter by setting the link_fault_mode RTL parameter to the value of lf_bidir.</p>
  [7] local_fault_status write-1-clears — <b>local_fault_status:</b> <p>Asserted when the RX MAC of the corresponding Ethernet channel detects a local fault: the RX PCS detected a problem that prevents it from receiving data. This signal is functional only if you set the Choose Link Fault generation option parameter to the value of Bidirectional or Unidirectional in the parameter editor or if you overwrite the parameter editor parameter by setting the link_fault_mode RTL parameter to the value of lf_bidir or lf_unidir. </p>
  [6] unidirectional_en ro — <b>unidirectional_en:</b> <p>Asserted if the IP core includes Clause 66 for unidirectional support. This signal is available if you turn on Enable link fault generation in the parameter editor. </p>
  [5] link_fault_gen_en ro — <b>link_fault_gen_en:</b> <p>Asserted if the IP core includes Clause 66 for unidirectional support. This signal is available if you turn on Enable link fault generation in the parameter editor. </p>
  [4] rx_block_lock ro — <b>rx_block_lock:</b> <p>Asserted when the corresponding Ethernet channel completes 66-bit block boundary alignment on all PCS lanes. Each channel has its own block lock signal. </p>
  [3] rx_am_lock ro — <b>rx_am_lock:</b> <p>Asserted when the RX PCS completes detection of alignment markers and deskew of the virtual PCS lanes in the corresponding Ethernet 100G channel. </p>
  [2] o_cdr_lock ro — <b>o_cdr_lock:</b> <p>Indicates that the recovered clocks are locked to data. The o_clk_rec_div64[n] and o_clk_rec_div66[n] clocks are reliable only after o_cdr_lock[n] is asserted. </p>
  [1] o_rx_hi_ber ro — <b>o_rx_hi_ber:</b> <p>Asserted to indicate the RX PCS of the corresponding Ethernet channel is in a HI BER state according to Figure 82-15 in the IEEE 802.3- 2015 Standard. The IP core uses this signal in autonegotiation and link training. </p>
  [0] o_ehip_ready ro — <b>o_ehip_ready:</b> <p>The Ethernet channel deasserts this signal in response to an i_csr_rst_n or i_tx_rst_n reset, or either of the corresponding soft resets. After the reset process completes, the channel reasserts this signal to indicate that the Hard IP for Ethernet block has completed initialization and is ready to interoperate with the main Intel Stratix 10 die. While the o_ehip_ready signal is low, the channel's datapath is not ready for data on the client interface nor ready for register accesses on the Ethernet reconfiguration interface.</p>
{0xC0+4i} sscsrif_hssi_eth_port{i}_status rw (i=12..15) — <b>HSSI Ethernet port{i} Status (Depends on NUM_PORTS parameter, read returns reserved value 0 if port does not exist) </b>
  [28] remote_fault_status_direct ro — <b>remote_fault_status:</b> <p>Asserted when the RX MAC of the corresponding Ethernet channel detects a remote fault: the remote link partner sent remote fault ordered sets indicating that it is unable to receive data. This signal is functional only if you set the Choose Link Fault generation option parameter to the value of Bidirectional in the parameter editor or if you overwrite the parameter editor parameter by setting the link_fault_mode RTL parameter to the value of lf_bidir.</p>
  [27] local_fault_status_direct ro — <b>local_fault_status:</b> <p>Asserted when the RX MAC of the corresponding Ethernet channel detects a local fault: the RX PCS detected a problem that prevents it from receiving data. This signal is functional only if you set the Choose Link Fault generation option parameter to the value of Bidirectional or Unidirectional in the parameter editor or if you overwrite the parameter editor parameter by setting the link_fault_mode RTL parameter to the value of lf_bidir or lf_unidir. </p>
  [26] parity_error write-1-clears — <b>Parity Error on received packet </b>
  [25] o_ehip7_tx_pll_locked ro — <b>o_ehip7_tx_pll_locked: </b> <p> PTP channels Tx_pll_locked (o_ehip{0..NUM_PORT/2}_tx_pll_locked, applicable only in E-tile. </p>
  [24] o_ehip6_tx_pll_locked ro — <b>o_ehip6_tx_pll_locked: </b> <p> PTP channels Tx_pll_locked (o_ehip{0..NUM_PORT/2}_tx_pll_locked, applicable only in E-tile. </p>
  [23] tx_pll_locked ro — <b>Tx_pll_locked: </b> <p> Tx Ethernet port pll lock </p>
  [22] rx_pcs_ready ro — <b>Rx_pcs_ready:</b> <p> Asserted when the RX lanes of the corresponding Ethernet port are fully aligned and ready to receive data. </p>
  [21] tx_lanes_stable ro — <b>Tx_lanes_stable:</b> <p> Asserted when physical TX lanes are stable and ready to transmit data for the corresponding Ethernet port. </p>
  [20] cal_err ro — <b>cal_err:</b> <p>Calibration Error Status.This bit reports the error status of ical/pcal at power on. </p>
  [19] load_recipe_err ro — <b>load_recipe_err:</b> <p>Load Recipe Error Status.This bit reports the error status of load PMA recipe at power on. </p>
  [18] eth_mode ro — <b>eth_mode:</b> <p>Ethernet mode. This signal is set to 1 when the MAC function is configured to operate at 1000 Mbps; set to 0 when it is configured to operate at 10/100 Mbps. Only applicable for TSE_MAC profile. Reserved for other profiles. </p>
  [17] ena_10 ro — <b>ena_10:</b> <p>10 Mbps enable. This signal is set to 1 to indicate that the PHY interface should operate at 10 Mbps. Valid only when the eth_mode signal is set to 0. Only applicable for TSE_MAC profile. Reserved for other profiles. </p>
  [16] set_1000 ro — <b>set_1000:</b> <p>Gigabit mode selection. Can be driven to 1 by an external device, for example a PHY device, to set the MAC function to operate in gigabit. When set to 0, the MAC is set to operate in 10/100 Mbps. This signal is ignored when the ETH_SPEED bit in the command_config register is set to 1. Only applicable for TSE_MAC profile. Reserved for other profiles. </p>
  [15] set_10 ro — <b>set_10:</b> <p>10 Mbps selection. Can be driven to 1 by an external device, for example a PHY device, to indicate that the MAC function is connected to a 10-Mbps PHY device. When set to 0, the MAC function is set to operate in 100-Mbps or gigabit mode. This signal is ignored when the ETH_SPEED or ENA_10 bit in the command_config register is set to 1. The ENA_10 bit has a higher priority than this signal. Only applicable for TSE_MAC profile. Reserved for other profiles. </p>
  [14:13] mac_eccstatus ro — <b>mac_eccstatus[1:0]:</b> <p>Indicates the ECC status. This signal is synchronized to the reg_clk clock domain. 11: An uncorrectable error occurred and the error data appears at the output. 10: A correctable error occurred and the error has been corrected at the output. However, the memory array has not been updated. 01: Not valid. 00: No error. Only applicable for TSE_MAC profile. Reserved for other profiles. </p>
  [12:11] pcs_eccstatus ro — <b>pcs_eccstatus[1:0]:</b> <p>Indicates the ECC status. This signal is synchronized to the reg_clk clock domain. 11: An uncorrectable error occurred and the error data appears at the output. 10: A correctable error occurred and the error has been corrected at the output. However, the memory array has not been updated. 01: Not valid. 00: No error Only applicable for TSE_PCS profile. Reserved for other profiles. </p>
  [10] unidirectional_remote_fault_dis ro — <b>unidirectional_remote_fault_dis:</b> <p>When asserted, this signal indicates the state of the tx_unidir_control register bit 1. </p>
  [9] unidirectional_force_remote_fault ro — <b>unidirectional_force_remote_fault:</b> <p>When asserted, this signal indicates the state of the tx_unidir_control register bit 2. </p>
  [8] remote_fault_status write-1-clears — <b>remote_fault_status:</b> <p>Asserted when the RX MAC of the corresponding Ethernet channel detects a remote fault: the remote link partner sent remote fault ordered sets indicating that it is unable to receive data. This signal is functional only if you set the Choose Link Fault generation option parameter to the value of Bidirectional in the parameter editor or if you overwrite the parameter editor parameter by setting the link_fault_mode RTL parameter to the value of lf_bidir.</p>
  [7] local_fault_status write-1-clears — <b>local_fault_status:</b> <p>Asserted when the RX MAC of the corresponding Ethernet channel detects a local fault: the RX PCS detected a problem that prevents it from receiving data. This signal is functional only if you set the Choose Link Fault generation option parameter to the value of Bidirectional or Unidirectional in the parameter editor or if you overwrite the parameter editor parameter by setting the link_fault_mode RTL parameter to the value of lf_bidir or lf_unidir. </p>
  [6] unidirectional_en ro — <b>unidirectional_en:</b> <p>Asserted if the IP core includes Clause 66 for unidirectional support. This signal is available if you turn on Enable link fault generation in the parameter editor. </p>
  [5] link_fault_gen_en ro — <b>link_fault_gen_en:</b> <p>Asserted if the IP core includes Clause 66 for unidirectional support. This signal is available if you turn on Enable link fault generation in the parameter editor. </p>
  [4] rx_block_lock ro — <b>rx_block_lock:</b> <p>Asserted when the corresponding Ethernet channel completes 66-bit block boundary alignment on all PCS lanes. Each channel has its own block lock signal. </p>
  [3] rx_am_lock ro — <b>rx_am_lock:</b> <p>Asserted when the RX PCS completes detection of alignment markers and deskew of the virtual PCS lanes in the corresponding Ethernet 100G channel. </p>
  [2] o_cdr_lock ro — <b>o_cdr_lock:</b> <p>Indicates that the recovered clocks are locked to data. The o_clk_rec_div64[n] and o_clk_rec_div66[n] clocks are reliable only after o_cdr_lock[n] is asserted. </p>
  [1] o_rx_hi_ber ro — <b>o_rx_hi_ber:</b> <p>Asserted to indicate the RX PCS of the corresponding Ethernet channel is in a HI BER state according to Figure 82-15 in the IEEE 802.3- 2015 Standard. The IP core uses this signal in autonegotiation and link training. </p>
  [0] o_ehip_ready ro — <b>o_ehip_ready:</b> <p>The Ethernet channel deasserts this signal in response to an i_csr_rst_n or i_tx_rst_n reset, or either of the corresponding soft resets. After the reset process completes, the channel reasserts this signal to indicate that the Hard IP for Ethernet block has completed initialization and is ready to interoperate with the main Intel Stratix 10 die. While the o_ehip_ready signal is low, the channel's datapath is not ready for data on the client interface nor ready for register accesses on the Ethernet reconfiguration interface.</p>
0x100 sscsrif_hssi_tse_ctrl rw — <b>HSSI TSE Control (Only applicable for TSE_MAC profile, Reserved for other profiles) </b>
  [1] Magic_sleep_n — <b>Magic_sleep_n:</b> <p>Assert this active-low signal to put the node into a power-down state. If magic packets are supported (the MAGIC_ENA bit in the command_config register is set to 1), the receiver logic stops writing data to the receive FIFO buffer and the magic packet detection logic is enabled. Setting this signal to 1 restores the normal frame reception mode. This signal is present only if the Enable magic packet detection option is turned on. </p>
  [0] Magic_wakeup ro — <b>Magic_wakeup:</b> <p>If the MAC function is in the power-down state, the MAC function asserts this signal to indicate that a magic packet has been detected and the node is requested to restore its normal frame reception mode. This signal is present only if the Enable magic packet detection option is turned on. </p>
0x108 sscsrif_hssi_debug_ctrl rw reset 0x18800 — <b>HSSI Debug Control for LED Status Signals </b>
  [18:11] led_status_blinking_timer — <b> LED status signal blinking timer (in terms of 10ms) </b>
  [10] led_status_override_enable — <b> LED status override enable: </b> <p> Enable the LED status interface signals override. </p>
  [9:6] port_led_status_override — <b>Port N LED status override:</b> <p>Select which port to override the LED status interface signals. LED status override bit must be set to 1 together with Port N LED status override ports and values to take effect. 4'b1111 - port 15 : 4'b0000 - port 0. </p>
  [5:3] override_led_status — <b> Override value for portN_led_status[5:3], used for debug and testing </b>
  [2:0] override_led_speed — <b> Override value for portN_led_speed[2:0], used for debug and testing.</b>
0x10C sscsrif_hssi_hotplug_debug_ctrl rw reset 0x9C400000 — <b>HSSI Debug Control for HOTPLUG module </b>
  [31:0] hotplug_control — <b> Hotplug control bits used for debug and testing.</b>
0x110 sscsrif_hssi_hotplug_debug_sts — <b>HSSI Debug Status for Hotplug </b>
  [7:0] hotplug_status — <b> Hotplug module status.</b>
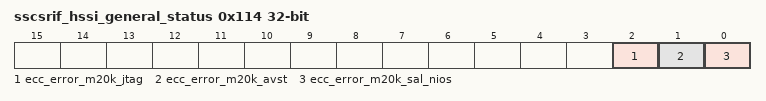
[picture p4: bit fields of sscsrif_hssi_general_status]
0x114 sscsrif_hssi_general_status rw — <b>HSSI General Status </b>
  [2] ecc_error_m20k_jtag write-1-clears — <b> ECC error on M20K </b> <p> 1'b1 - ECC error detected </p> <p> 1'b0 - No ECC error detected </p> <p> [2:2] - JTAG Avalon Master M20K Error </p>
  [1] ecc_error_m20k_avst write-1-clears — <b> ECC error on M20K </b> <p> 1'b1 - ECC error detected </p> <p> 1'b0 - No ECC error detected </p> <p> [1:1] - AVST Bridge M20K Error (M20K ECC status from all active ports OR together)</p>
  [0] ecc_error_m20k_sal_nios write-1-clears — <b> ECC error on M20K </b> <p> 1'b1 - ECC error detected </p> <p> 1'b0 - No ECC error detected </p> <p> [0:0] - SAL NIOS M20K Error </p>
